VERSION "HIPBNYYYYYYYYYYYYYYYYYYYYYYYYYYYYYYYYYYYYY/4/%%%/4/'%**4YYY///"

NS_ :

BS_:

BU_:

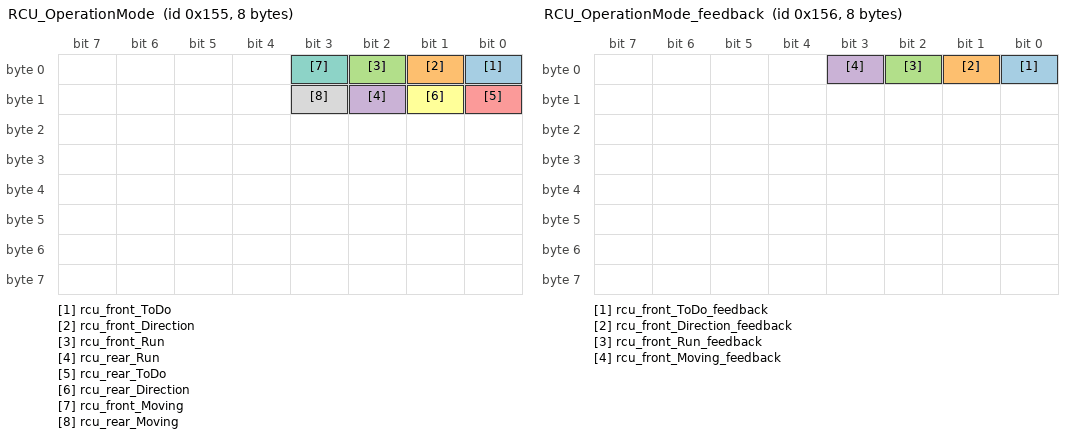
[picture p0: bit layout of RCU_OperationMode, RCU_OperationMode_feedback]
BO_ 341 RCU_OperationMode: 8 Vector__XXX
 SG_ rcu_front_ToDo : 0|1@1+ (1,0) [0|0] "" Vector__XXX
 SG_ rcu_front_Direction : 1|1@1+ (1,0) [0|0] "" Vector__XXX
 SG_ rcu_front_Run : 2|1@1+ (1,0) [0|0] "" Vector__XXX
 SG_ rcu_rear_Run : 10|1@1+ (1,0) [0|0] "" Vector__XXX
 SG_ rcu_rear_ToDo : 8|1@1+ (1,0) [0|0] "" Vector__XXX
 SG_ rcu_rear_Direction : 9|1@1+ (1,0) [0|0] "" Vector__XXX
 SG_ rcu_front_Moving : 3|1@1+ (1,0) [0|0] "" Vector__XXX
 SG_ rcu_rear_Moving : 11|1@1+ (1,0) [0|0] "" Vector__XXX

BO_ 342 RCU_OperationMode_feedback: 8 Vector__XXX
 SG_ rcu_front_ToDo_feedback : 0|1@1+ (1,0) [0|0] "" Vector__XXX
 SG_ rcu_front_Direction_feedback : 1|1@1+ (1,0) [0|0] "" Vector__XXX
 SG_ rcu_front_Run_feedback : 2|1@1+ (1,0) [0|0] "" Vector__XXX
 SG_ rcu_front_Moving_feedback : 3|1@1+ (1,0) [0|0] "" Vector__XXX
